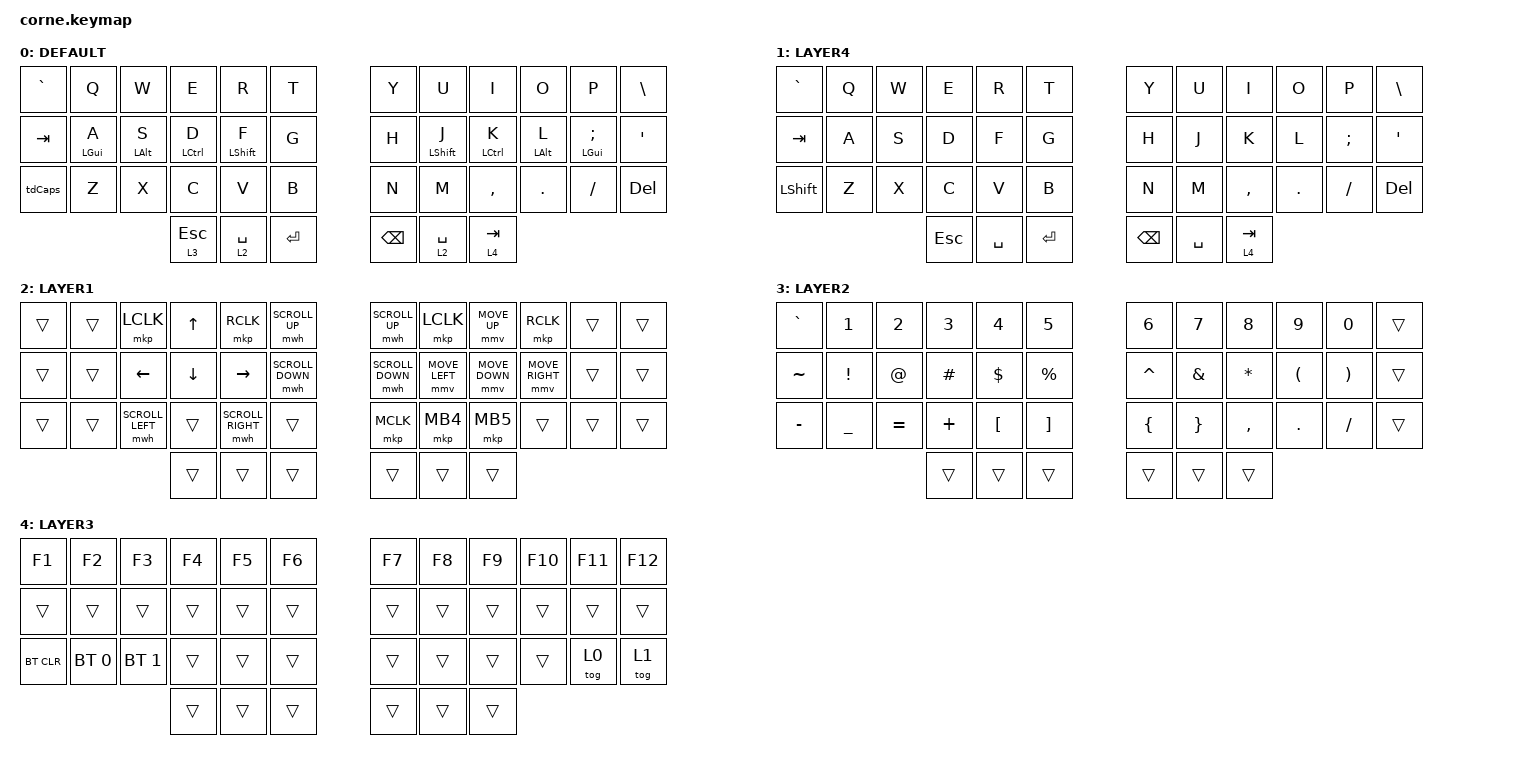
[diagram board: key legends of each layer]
/*
 * Copyright (c) 2020 The ZMK Contributors
 *
 * SPDX-License-Identifier: MIT
 */

#include <behaviors.dtsi>
#include <dt-bindings/zmk/mouse.h>
#include <dt-bindings/zmk/bt.h>
#include <dt-bindings/zmk/keys.h>

#define DEFAULT 0
#define LAYER1  1
#define LAYER2  2
#define LAYER3  3
#define LAYER4  4
#define LAYER5  5
#define U_MOUSE_MOVE_MAX 1200                     /* <--- New max speed setting (default: 600) */

#undef MOVE_UP
#undef MOVE_DOWN
#undef MOVE_LEFT
#undef MOVE_RIGHT

#define MOVE_UP MOVE_VERT(-U_MOUSE_MOVE_MAX)
#define MOVE_DOWN MOVE_VERT(U_MOUSE_MOVE_MAX)
#define MOVE_LEFT MOVE_HOR(-U_MOUSE_MOVE_MAX)
#define MOVE_RIGHT MOVE_HOR(U_MOUSE_MOVE_MAX)
#define U_MOUSE_SCROLL_MAX 80                    /* <--- New max speed setting (default: 10) */

#undef SCROLL_UP
#undef SCROLL_DOWN
#undef SCROLL_LEFT
#undef SCROLL_RIGHT

#define SCROLL_UP SCROLL_VERT(U_MOUSE_SCROLL_MAX)
#define SCROLL_DOWN SCROLL_VERT(-U_MOUSE_SCROLL_MAX)
#define SCROLL_LEFT SCROLL_HOR(-U_MOUSE_SCROLL_MAX)
#define SCROLL_RIGHT SCROLL_HOR(U_MOUSE_SCROLL_MAX)

&mmv {
    time-to-max-speed-ms = <1000>;
    acceleration-exponent = <1>;
};

&mwh {
    time-to-max-speed-ms = <500>;
    acceleration-exponent = <1>;
};

/ {
    behaviors {
        gqt: global-quick-tap {
            compatible = "zmk,behavior-hold-tap";
            label = "GLOBAL_QUICK_TAP";
            #binding-cells = <2>;
            flavor = "tap-preferred";
            tapping-term-ms = <200>;
            quick-tap-ms = <140>;
            global-quick-tap;
            bindings =
                <&kp>,
                <&kp>;
        };
        bhm: balanced_homerow_mods {
            compatible = "zmk,behavior-hold-tap";
            label = "HOMEROW_MODS";
            #binding-cells = <2>;
            tapping-term-ms = <200>;// <---[[moderate duration]]
            quick-tap-ms = <0>;
            flavor = "balanced";
            bindings =
                <&kp>,
                <&kp>;
        };
        tdCaps: tap_dance_0 {
            compatible = "zmk,behavior-tap-dance";
            label = "TAP_DANCE_0";
            #binding-cells = <0>;
            tapping-term-ms = <200>;
            bindings =
                <&kp LSHIFT>,
                <&kp CAPSLOCK>;
        };
        tdGame: tap_dance_1 {
            compatible = "zmk,behavior-tap-dance";
            label = "TAP_DANCE_1";
            #binding-cells = <0>;
            tapping-term-ms = <200>;
            bindings =
                <&kp GRAVE>,
                <&tog 4>;
        };
    };

    combos {
        compatible = "zmk,combos";
    };

    keymap {
        compatible = "zmk,keymap";

        DEFAULT {
            // -----------------------------------------------------------------------------------------
            // | TAB  |  Q  |  W  |  E  |  R  |  T  |       |  Y  |  U   |  I  |  O  |  P  |  \   |
            // | CTRL |  A  |  S  |  D  |  F  |  G  |       |  H  |  J   |  K  |  L  |  ;  |  '   |
            // | SHFT |  Z  |  X  |  C  |  V  |  B  |       |  N  |  M   |  ,  |  .  |  /  | ESC  |
            //                    | GUI | LWR | SPC |       | ENT | RSE  | ALT |

            bindings = <
&kp GRAVE        &kp Q        &kp W         &kp E          &kp R      &kp T            &kp Y          &kp U         &kp I        &kp O           &kp P    &kp BSLH
  &kp TAB  &bhm LGUI A  &bhm LALT S  &bhm LCTRL D  &bhm LSHIFT F      &kp G            &kp H  &bhm LSHIFT J  &bhm LCTRL K  &bhm LALT L  &bhm LGUI SEMI     &kp SQT
  &tdCaps        &kp Z        &kp X         &kp C          &kp V      &kp B            &kp N          &kp M     &kp COMMA      &kp DOT        &kp FSLH  &kp DELETE
                                     &lt 3 ESCAPE    &lt 2 SPACE  &kp ENTER    &kp BACKSPACE    &lt 2 SPACE     &lt 4 TAB
            >;
        };

        LAYER4 {
            bindings = <
     &kp GRAVE  &kp Q  &kp W       &kp E      &kp R      &kp T            &kp Y      &kp U      &kp I       &kp O          &kp P  &kp BACKSLASH
       &kp TAB  &kp A  &kp S       &kp D      &kp F      &kp G            &kp H      &kp J      &kp K       &kp L  &kp SEMICOLON        &kp SQT
&kp LEFT_SHIFT  &kp Z  &kp X       &kp C      &kp V      &kp B            &kp N      &kp M  &kp COMMA  &kp PERIOD      &kp SLASH     &kp DELETE
                              &kp ESCAPE  &kp SPACE  &kp ENTER    &kp BACKSPACE  &kp SPACE  &lt 4 TAB
            >;
        };

        LAYER1 {
            // -----------------------------------------------------------------------------------------
            // |   |   |      |  UP  |       |   |       |    |    |    |    |    |    |
            // |   |   | LEFT | DOWN | RIGHT |   |       |    |    |    |    |    |    |
            // |   |   |      |      |       |   |       |    |    |    |    |    |    |
            //                |      |       |   |       |    |    |    |

            bindings = <
&trans  &trans         &mkp LCLK    &kp UP          &mkp RCLK    &mwh SCROLL_UP      &mwh SCROLL_UP       &mkp LCLK    &mmv MOVE_UP        &mkp RCLK  &trans  &trans
&trans  &trans          &kp LEFT  &kp DOWN          &kp RIGHT  &mwh SCROLL_DOWN    &mwh SCROLL_DOWN  &mmv MOVE_LEFT  &mmv MOVE_DOWN  &mmv MOVE_RIGHT  &trans  &trans
&trans  &trans  &mwh SCROLL_LEFT    &trans  &mwh SCROLL_RIGHT            &trans           &mkp MCLK        &mkp MB4        &mkp MB5           &trans  &trans  &trans
                                    &trans             &trans            &trans              &trans          &trans          &trans
            >;
        };

        LAYER2 {
            // -----------------------------------------------------------------------------------------
            // |  TAB |  1  |  2  |  3  |  4  |  5  |   |  6  |  7  |  8  |  9  |  0  | BKSP |
            // | BTCLR| BT1 | BT2 | BT3 | BT4 | BT5 |   | LFT | DWN |  UP | RGT |     |      |
            // | SHFT |     |     |     |     |     |   |     |     |     |     |     |      |
            //                    | GUI |     | SPC |   | ENT |     | ALT |

            bindings = <
&kp GRAVE     &kp N1     &kp N2    &kp N3            &kp N4             &kp N5            &kp N6           &kp N7     &kp N8                &kp N9                 &kp N0  &trans
&kp TILDE   &kp EXCL     &kp AT  &kp HASH        &kp DOLLAR        &kp PERCENT         &kp CARET    &kp AMPERSAND   &kp STAR  &kp LEFT_PARENTHESIS  &kp RIGHT_PARENTHESIS  &trans
&kp MINUS  &kp UNDER  &kp EQUAL  &kp PLUS  &kp LEFT_BRACKET  &kp RIGHT_BRACKET    &kp LEFT_BRACE  &kp RIGHT_BRACE  &kp COMMA               &kp DOT              &kp SLASH  &trans
                                   &trans            &trans             &trans            &trans           &trans     &trans
            >;
        };

        LAYER3 {
            // -----------------------------------------------------------------------------------------
            // |  TAB |  !  |  @  |  #  |  $  |  %  |   |  ^  |  &  |  *  |  (  |  )  | BKSP |
            // | CTRL |     |     |     |     |     |   |  -  |  =  |  [  |  ]  |  \  |  `   |
            // | SHFT |     |     |     |     |     |   |  _  |  +  |  {  |  }  | "|" |  ~   |
            //                    | GUI |     | SPC |   | ENT |     | ALT |

            bindings = <
    &kp F1        &kp F2        &kp F3  &kp F4  &kp F5  &kp F6    &kp F7  &kp F8  &kp F9  &kp F10  &kp F11  &kp F12
    &trans        &trans        &trans  &trans  &trans  &trans    &trans  &trans  &trans   &trans   &trans   &trans
&bt BT_CLR  &bt BT_SEL 0  &bt BT_SEL 1  &trans  &trans  &trans    &trans  &trans  &trans   &trans   &tog 0   &tog 1
                                        &trans  &trans  &trans    &trans  &trans  &trans
            >;
        };
    };
};
